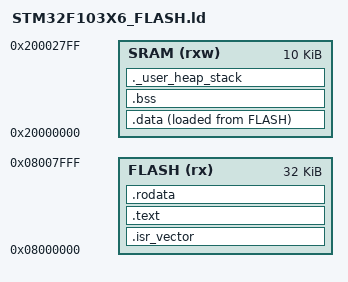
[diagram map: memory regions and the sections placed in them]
MEMORY
{
    FLASH (rx) : ORIGIN = 0x08000000, LENGTH = 32K
    SRAM (rxw) : ORIGIN = 0X20000000, LENGTH = 10K
}

_esram = ORIGIN(SRAM) + LENGTH(SRAM);
_estack = _esram;

_Min_Heap_Size = 0x200;      /* required amount of heap  */
_Min_Stack_Size = 0x400; /* required amount of stack */

SECTIONS
{
    .isr_vector :
    {
        . = ALIGN(4);
        KEEP(*(.isr_vector))
        . = ALIGN(4);
    } > FLASH

    .text :
    {
        . = ALIGN(4);
        _stext = .;
        KEEP(*(.text*))
        . = ALIGN(4);
        _etext = .;
    } > FLASH

    .data :
    {
        . = ALIGN(4);
        _sdata = .;
        *(.data*)
        . = ALIGN(4);
        _edata = .;
    } > SRAM AT > FLASH
    _sidata = LOADADDR(.data);

    .rodata :
    {
        . = ALIGN(4);
        _srodata = .;
        *(.rodata*)
        . = ALIGN(4);
        _erodata = .;
    } > FLASH
    _sirodata = LOADADDR(.rodata);

    .bss :
    {
        . = ALIGN(4);
        _sbss = .;
        *(.bss*)
        . = ALIGN(4);
        _ebss = .;
    } > SRAM

    ._user_heap_stack :
    {
        . = ALIGN(8);
        _end = .;
        . = . + _Min_Heap_Size;
        . = . + _Min_Stack_Size;
        . = ALIGN(8);
    } > SRAM
}
